# STM32WB05 register map
File version: 0.3
CPU: CM0+ r0p0, little endian, MPU, no FPU, 4 interrupt priority bits
Registers are 32-bit, read-write, reset 0x0 unless marked. A register's access mark holds for its fields unless they carry their own. Offsets are from the block's base; [hi:lo] are bit positions; 'fields as' and 'values as' point back to an identical list.

## RCC
Base 0x48400000
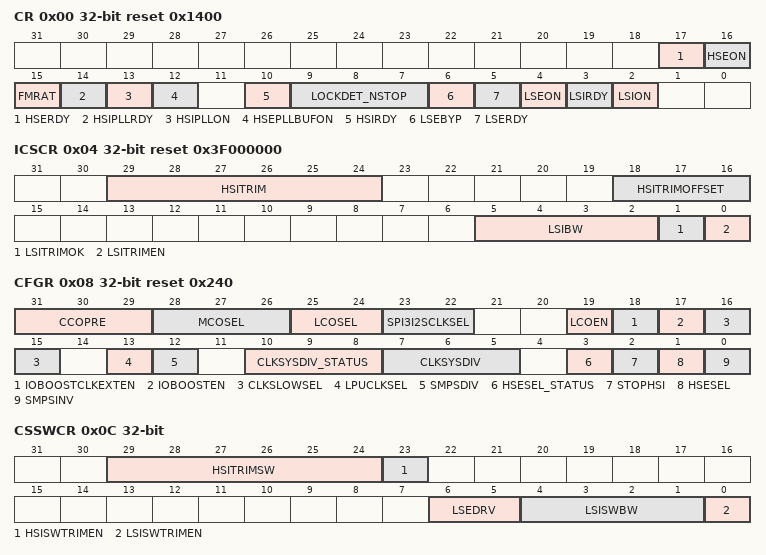
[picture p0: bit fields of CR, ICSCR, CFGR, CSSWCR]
0x00 CR reset 0x1400
  [17] HSERDY ro — External High Speed Clock ready flag. Set by hardware to indicate that HSE oscillator is stable.
    0=HSE oscillator not ready; 1=HSE oscillator ready
  [16] HSEON — External High Speed Clock enable. Set and reset by software. in low power mode, HSE is turned off.
    0=HSE oscillator OFF; 1=HSE oscillator ON
  [15] FMRAT — Force MR_BLE active transmission status (for debug purpose)
    0=no effect; 1=active_transmission is force to '1' whatever the HSIPLLRDY status
  [14] HSIPLLRDY ro — Internal High Speed Clock PLL ready flag.
    0=PLL is unlocked; 1=PLL is locked
  [13] HSIPLLON — Internal High Speed Clock PLL enable
    0=PLL is OFF; 1=PLL is ON
  [12] HSEPLLBUFON — External High Speed Clock Buffer for PLL RF2G4 enable. Set and reset by software.
    0=HSE PLL Buffer OFF; 1=HSE PLL Buffer ON
  [10] HSIRDY ro — Internal High Speed clock ready flag. Set by hardware to indicate that internal RC 64MHz oscillator is stable. This bit is activated only if the RC is enabled by HSION (it is not activated if the RC is enabled by an IP request).
    0=internal RC 64 MHz oscillator not ready; 1=internal RC 64 MHz oscillator ready
  [9:7] LOCKDET_NSTOP — Lock detector Nstop value When start_stop signal is high; a counter is incremented every 16 MHz clock cycle. When the counter reaches (NSTOP+1) x 64 value, the lock_det signal is set high indicating that the PLL is locked. As soon as the start_stop signal is low the counter is reset to 0.
  [6] LSEBYP — External Low Speed Clock bypass. Set and reset by software. Reset source only for this field: PORESETn
    0=LSE oscillator bypass OFF; 1=LSE oscillator bypass ON
  [5] LSERDY ro — External Low Speed Clock ready flag. Set by hardware to indicate that LSE oscillator is stable.
    0=LSE oscillator not ready; 1=LSE oscillator ready
  [4] LSEON — External Low Speed Clock enable. Set and reset by software. Reset source only for this field: PORESETn
    0=LSE oscillator OFF; 1=LSE oscillator ON
  [3] LSIRDY ro — Internal Low Speed oscillator Ready Set and reset by hardware to indicate when the Low Speed Internal RC oscillator is stable. Reset source only for this field: PORESETn
    0=LSI RC oscillator not ready; 1=LSI RC oscillator ready
  [2] LSION — Internal Low Speed oscillator enable Set and reset by software. Reset source only for this field: PORESETn
    0=LSI RC oscillator OFF; 1=LSI RC oscillator ON
0x04 ICSCR reset 0x3F000000
  [29:24] HSITRIM ro — High Speed Internal clock trimming. This value is loaded soon after the completion of the Option Byte Loading procedure. When max value 0x3f is set, HSI is less than 64MHz
  [18:16] HSITRIMOFFSET — ICSCR[18:16] = HSITRIMOFFSET[2:0]: High Speed oscillator signed trimming offset
    0=0 (+ 0 MHz / default); 1=1 (+0.5 MHz); 2=2 (+1MHz); 3=3 (+1.5 MHz); 4=-1 (-0.5 MHz); 5=-2 (-1MHz); 6=-3 (-1.5 MHz); 7=-4 (-2 MHz)
  [5:2] LSIBW ro — Trimming in test mode The value stored is the correspondent Engi Byte and represents the actual value driving the input of the hardware macro. This value is loaded soon after the completion of the Option Byte Loading procedure. This field is directly writeable only in Test Mode.
  [1] LSITRIMOK ro — LSITRIMOK: Low Speed oscillator trimming OK Set and reset by hardware to indicate when the Low Speed Internal RC oscillator has reached an optimal trimming of its bias current; this bit is only valid when LSITRIMEN is active.
    0=LSI Bias trimming (LSIBW) is not good; 1=LSI Bias trimming (LSIBW) value is OK
  [0] LSITRIMEN — Low Speed oscillator trimming enable Set and reset by software. Reset source only for this field: PORESETn
    0=LSI oscillator Bias trimming disabled; 1=LSI oscillator Bias trimming enabled
0x08 CFGR reset 0x240
  [31:29] CCOPRE — Configurable Clock Output Prescaler. Set and reset by software. Glitches propagation if CCOPRE is modified after CCO output is enabled. Others: not used
    0=CCO clock is divided by 1; 1=CCO clock is divided by 2; 2=CCO clock is divided by 4; 3=CCO clock is divided by 8; 4=CCO clock is divided by 16
  [28:26] MCOSEL — Main Configurable Clock Output Selection. Set and reset by software. Glitches propagation possible.
    0=MCO output disabled, no clock on MCO; 1=system clock selected; 2=na; 3=internal RC 64 MHz (HSI) oscillator clock selected; 4=external oscillator (HSE) clock selected; 5=internal RC 64 MHz (HSI) oscillator divided by 2048 and used as slow clock selected; 6=SMPS clock selected; 7=AUX ADC ANA clock selected
  [25:24] LCOSEL — Low speed Configurable Clock Output Selection. Set and reset by software. Glitches propagation possible. Reset source only for this field: PORESETn
    0=LCO output disabled, no clock on LCO; 1=internal 32 KHz (LSI_LPMU) oscillator clock selected; 2=internal 32 KHz (LSI) oscillator clock selected; 3=external 32 KHz (LSE) oscillator clock selected
  [23:22] SPI3I2SCLKSEL — Selection of I2S1 clock: 1x:64MHz peripheral clock
    0=16MHz peripheral clock (default); 1=32MHz peripheral clock
  [19] LCOEN — LCO output enable
  [18] IOBOOSTCLKEXTEN — IO BOOSTER clock enable as external clock Set and reset by software.
    0=does not use rcc clock (default); 1=uses rcc clock
  [17] IOBOOSTEN — IO BOOSTER enable Set and reset by software.
    0=does not enable IO BOOSTER; 1=enable IO BOOSTER
  [16:15] CLKSLOWSEL — slow clock source selection Set by software to select the clock source. This is no glitch free mechanism Reset source only for this field: PORESETn
    0=LSILMPU oscillator clock (default); 1=LSE oscillator clock used as slow clock; 2=LSI oscillator clock used as slow clock; 3=HSI_64M divided by 2048 used as slow clock
  [13] LPUCLKSEL — Selection of LPUART clock:
    0=16MHz peripheral clock (default); 1=LSE clock
  [12] SMPSDIV — SMPS clock prescaling factor to generate 4MHz or 8MHz
    0=div 2 when ANADIV=2 or 4 (default ); 1=div 4 when ANADIV=1 or 2
  [10:8] CLKSYSDIV_STATUS ro — CLKSYSDIV_STATUS: system clock frequency status Set and cleared by hardware to indicate the actual system clock frequency. This register must be read to be sure that the new frequency, selected by CLKSYSDIV, has been applied. 000: system clock frequency is 64 MHz 001: system clock frequency is 32 MHz 010: system clock frequency is 16 MHz 011: system clock frequency is 8 MHz 100: system clock frequency is 4 MHz 101: system clock frequency is 2 MHz 110: system clock frequency is 1 MHz 111: not used. The actual clock frequency switching can be delayed of up to 128 system clock cycles, depending on the RCC internal counter status at the moment the new CLKSYSDIV is applied
  [7:5] CLKSYSDIV — CLKSYSDIV: system clock divided factor from HSI_64M. 000: system clock frequency is 64 MHz (not available when HSESEL=1) 001: system clock frequency is 32 MHz 010: system clock frequency is 16 MHz 011: system clock frequency is 8 MHz * 100: system clock frequency is 4 MHz * 101: system clock frequency is 2 MHz * 110: system clock frequency is 1 MHz * 111: not used. *: If RCC_APB2ENR.MRBLEEN bit is set, writing in CLKSYSDIV one of those values is replaced by a 010b = 16 MHz writing at hardware level. Warning: if the software programs the 64 MHz frequency target while the RCC_CFGR.HSESEL=1, the hardware will switch the system clock tree on HSI64MPLL again (and restart HSIPLL64M analog block if RCC_CFGR.STOPHSI=1) To switch the system frequency between 64 / 32 / 16 MHz without risk when the MR_BLE is used, prefer the RCC_CSCMDR register to change the system frequency. the MR_BLE frequency must always be equal or less than the CPU/system clock to have functional radio.
  [3] HSESEL_STATUS ro — Clock source selection Status
    0=HSI clock source is requested (default); 1=HSE clock source is requested
  [2] STOPHSI — Stop HSI clock source request
    0=HSI is enabled (default); 1=disable HSI is requested
  [1] HSESEL — Clock source selection request:
    values as HSESEL_STATUS
  [0] SMPSINV — bit to control inversion of the SMPS clock
    0=SMPS clock not inverted (default value); 1=SMPS clock inverted (for debug)
0x0C CSSWCR
  [29:24] HSITRIMSW — High Speed Internal clock trimming value to set by SW.
  [23] HSISWTRIMEN — High Speed oscillator trimming by SW enable Set and reset by software.
    0=HSI oscillator Bias trimming by SW disabled; 1=HSI oscillator Bias trimming by SW enabled
  [6:5] LSEDRV — Maximum Crystal gm for Low Speed External XO (to connect to XTDRV of 32kHz LSE XO => into IO V33?) to amplify drinving capacity modulation Set by software. Reset source only for this field: PORESETn
    0=0.0, low drive capability; 1=0.1, medium low drive capability; 2=1.0, medium high drive capability; 3=1.1, highdrive capability
  [4:1] LSISWBW — Low Speed Internal clock trimming value to set by SW Reset source only for this field: PORESETn
  [0] LSISWTRIMEN — Low Speed oscillator trimming by SW enable Set and reset by software. Reset source only for this field: PORESETn
    0=LSI oscillator Bias trimming by SW disabled; 1=LSI oscillator Bias trimming by SW enabled
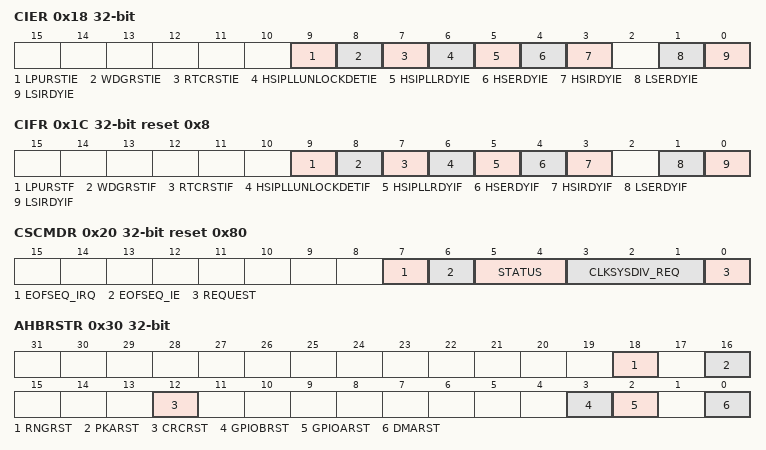
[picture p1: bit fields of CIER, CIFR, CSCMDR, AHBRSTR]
0x18 CIER
  [9] LPURSTIE — LPURSTIE: LPUART reset release interrupt enable.
    0=LPUART reset release interrupt is disabled; 1=LPUART reset release interrupt is enabled
  [8] WDGRSTIE — WDGRSTIE: Watchdog reset end Interrupt Enable. Set and reset by software to enable/disable interrupt caused by the watchdog reset end.
    0=interrupt disabled; 1=interrupt enabled
  [7] RTCRSTIE — RTCRSTIE: RTC reset end Interrupt Enable. Set and reset by software to enable/disable interrupt caused by the RTC reset end.
    0=HSI PLL unlock detection interrupt disabled; 1=HSI PLL unlock detection interrupt enabled
  [6] HSIPLLUNLOCKDETIE — HSIPLLUNLOCKDETIE: HSI PLL unlock detection Interrupt Enable. Set and reset by software to enable/disable interrupt caused by the HSI 64MHz PLL unlock.
    values as RTCRSTIE
  [5] HSIPLLRDYIE — HSI PLL Ready Interrupt Enable. Set and reset by software to enable/disable interrupt caused by the HSI 64MHz PLL locked on HSE.
    0=HSI PLL ready interrupt disabled; 1=HSI PLL ready interrupt enabled
  [4] HSERDYIE — HSE Ready Interrupt Enable Set and reset by software to enable/disable interrupt caused by the external HSE oscillator stabilization.
    0=HSE ready interrupt disabled; 1=HSE ready interrupt enabled
  [3] HSIRDYIE — HSI Ready Interrupt Enable. Set and reset by software to enable/disable interrupt caused by the internal RC 64MHz oscillator stabilization.
    0=HSI ready interrupt disabled; 1=HSI ready interrupt enabled
  [1] LSERDYIE — LSE Ready Interrupt Enable. Set and reset by software to enable/disable interrupt caused by the external 32 kHz oscillator stabilization.
    0=LSE ready interrupt disabled; 1=LSE ready interrupt enabled
  [0] LSIRDYIE — LSI Ready Interrupt Enable. Set and reset by software to enable/disable interrupt caused by internal RC 32 kHz oscillator stabilization.
    0=LSI ready interrupt disabled; 1=LSI ready interrupt enabled
0x1C CIFR reset 0x8
  [9] LPURSTF — LPUART reset release flag
    0=no LPUART reset release event occurred; 1=LPUART reset release event occurred
  [8] WDGRSTIF — WDG reset end Interrupt Flag. Raised when reset is released on 32kHz clock
  [7] RTCRSTIF — RTC reset end Interrupt Flag. Raised when reset is released on 32kHz clock
  [6] HSIPLLUNLOCKDETIF — HSIPLLUNLOCKDETIF: HSI PLL unlock detection Interrupt Flag.
  [5] HSIPLLRDYIF — HSI PLL Ready Interrupt Flag. Set by hardware when HSI PLL 64MHz becomes stable.
    0=No clock ready interrupt caused by the HSI PLL64 MHz oscillator; 1=Clock ready interrupt caused by the HSI PLL64 MHz oscillator
  [4] HSERDYIF — HSE Ready Interrupt Flag. Set by hardware when HSE becomes stable.
    0=No clock ready interrupt caused by the HSE oscillator; 1=Clock ready interrupt caused by the HSE oscillator
  [3] HSIRDYIF — HSI Ready Interrupt Flag. Set by hardware when HSI becomes stable.
    0=No clock ready interrupt caused by the HSI oscillator; 1=Clock ready interrupt caused by the HSI oscillator
  [1] LSERDYIF — LSE Ready Interrupt Flag. Set by hardware when LSE clock becomes stable.
    0=No clock ready interrupt caused by the LSE oscillator; 1=Clock ready interrupt caused by the LSE oscillator
  [0] LSIRDYIF — LSI Ready Interrupt flag Set by hardware when LSI clock becomes stable.
    0=No clock ready interrupt caused by the internal RC 32 KHz oscillator; 1=Clock ready interrupt caused by the internal RC 32 kHz oscillator
0x20 CSCMDR reset 0x80
  [7] EOFSEQ_IRQ — End of Sequence flag Set by hardware when clock system swtich is ended
    0=No end of sequence event occured; 1=End of sequece event occured
  [6] EOFSEQ_IE — End of sequence Interrupt Enable. Set and reset by software to enable/disable interrupt caused by the clock system switch.
    0=End of sequence interrupt disabled; 1=End of sequence interrupt enabled
  [5:4] STATUS ro — Status of clock switch sequence
    0=IDLE no switch requested; 1=ONGOING clock frequency switch is ongoing; 2=DONE clock frequency switch done
  [3:1] CLKSYSDIV_REQ — system clock dividing factor from HSI_64M requested Note: behavior depends on BLEEN in APB2ENR register
    0=div 1 (sys clock 64M); 1=div 2 (sys clock 32M); 2=div 4 (sys clock 16M); 3=div 8 (sys clock 8M); 4=div 16 (sys clock 4M); 5=div 32 (sys clock 2M); 6=div 64 (sys clock 1M)
  [0] REQUEST — Request for system clock switching Cleared by hardware when system clock frequency switch is done
    0=To cancel an ongiong request - still possible until IRQ assertion; 1=To update the system clock frequency
0x30 AHBRSTR
  [18] RNGRST — RNG reset Set and reset by software.
    0=does not reset; 1=resets
  [16] PKARST — PKA reset Set and reset by software.
    0=does not reset; 1=resets
  [12] CRCRST — CRC reset Set and reset by software.
    0=does not reset CRC; 1=resets CRC
  [3] GPIOBRST — GPIOB reset Set and reset by software.
    0=does not reset; 1=resets
  [2] GPIOARST — GPIOA reset Set and reset by software.
    0=does not reset; 1=resets
  [0] DMARST — DMA and DMAMUX reset Set and reset by software.
    0=does not reset DMA; 1=resets DMA
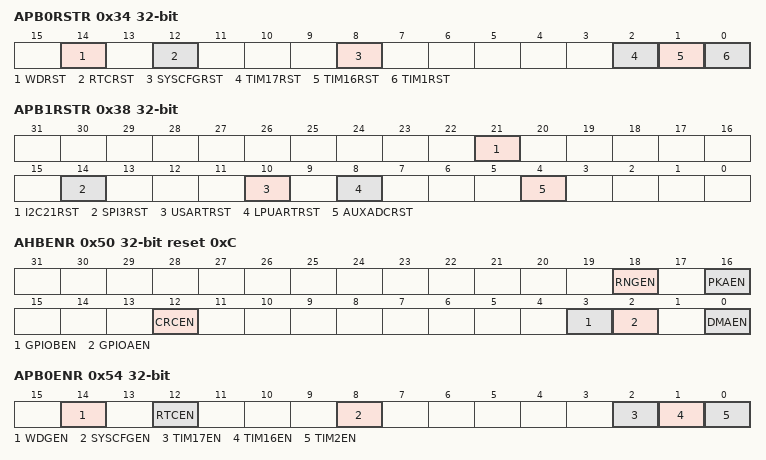
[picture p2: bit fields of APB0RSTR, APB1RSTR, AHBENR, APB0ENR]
0x34 APB0RSTR
  [14] WDRST — WATCHDOG reset Set and reset by software.
    0=does not reset; 1=resets
  [12] RTCRST — RTC reset Set and reset by software.
    0=does not reset; 1=resets
  [8] SYSCFGRST — SYSTEM CONFIG reset Set and reset by software.
    0=does not reset; 1=resets
  [2] TIM17RST — TIM17 reset
    0=TIM17 IP is not under reset; 1=TIM17 IP is under reset
  [1] TIM16RST — TIM16 reset
    0=TIM16 IP is not under reset; 1=TIM16 IP is under reset
  [0] TIM1RST — TIM1: Advanced Timer reset Set and reset by software.
    0=does not reset; 1=resets
0x38 APB1RSTR
  [all] fields
    0=does not reset; 1=resets
  [21] I2C21RST — I2C1 reset Set and reset by software.
  [14] SPI3RST — SPI3 reset Set and reset by software.
  [10] USARTRST — USART reset Set and reset by software.
  [8] LPUARTRST — LPUART reset Set and reset by software.
  [4] AUXADCRST — AUXADC reset for Aux-ADC digital clock Set and reset by software.
0x40 APB2RSTR
  [0] BLERST — BLE reset.
0x50 AHBENR reset 0xC
  [18] RNGEN — RNG clock enable Set and enable by software.
    0=does not enable; 1=enable
  [16] PKAEN — PKA clock enable Set and enable by software.
    0=does not enable; 1=enable
  [12] CRCEN — CRC enable Set and enable by software.
    0=does not enable; 1=enable
  [3] GPIOBEN — GPIOB enable. It must be enabled by default
  [2] GPIOAEN — GPIOA enable. It must be enabled by default
  [0] DMAEN — DMA and DMAMUX enable Set and enable by software.
    0=does not enable; 1=enable
0x54 APB0ENR
  [14] WDGEN — Watchdog clock enable. Set and enable by software.
    0=does not enable; 1=enable
  [12] RTCEN — RTC clock enable Set and enable by software. Reset source only for this field: PORESETn
    0=does not enable; 1=enable
  [8] SYSCFGEN — SYSTEM CONFIG enable Set and enable by software.
    0=does not enable; 1=enable
  [2] TIM17EN — TIM17 enable
    0=TIM17 IP is clock gated; 1=TIM17 IP is clocked
  [1] TIM16EN — TIM16 enable
    0=TIM16 IP is clock gated; 1=TIM16 IP is clocked
  [0] TIM2EN — TIM2: Advanced Timer clock enable Set and enable by software.
    0=does not enable; 1=enable
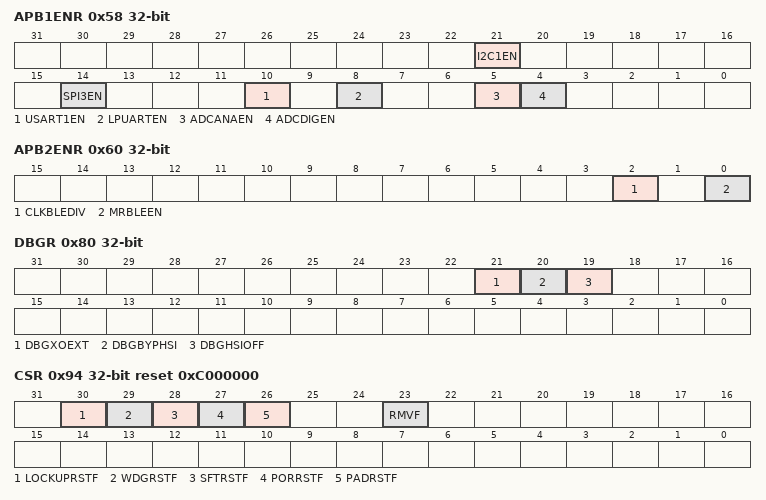
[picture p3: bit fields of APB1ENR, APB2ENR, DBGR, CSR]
0x58 APB1ENR
  [all] fields
    0=does not enable; 1=enable
  [21] I2C1EN — I2C1 clock enable Set and enable by software.
  [14] SPI3EN — SPI3 clock enable Set and enable by software.
  [10] USART1EN — USART clock enable Set and enable by software.
  [8] LPUARTEN — LPUART clock enable Set and enable by software.
  [5] ADCANAEN — ADC clock enable for Aux-ADC analog clock Set and enable by software.
  [4] ADCDIGEN — AUXADC clock enable for Aux-ADC digital clock Set and enable by software.
0x60 APB2ENR
  [2] CLKBLEDIV — MR_BLE clock frequency selection when RCC_APB2ENR.MRBLEEN=1
    0=32MHz; 1=16MHz
  [0] MRBLEEN — MR_BLE enable
    0=MR_BLE IP is clock gated; 1=MR_BLE IP is clocked
0x80 DBGR
  [21] DBGXOEXT — used for debug mode with HSE bypassed by FXTAL_IN clock and ZIV12 output used.
  [20] DBGBYPHSI — used for debug mode with HSI bypassed by HSE
  [19] DBGHSIOFF — used for debug or test
0x94 CSR reset 0xC000000
  [30] LOCKUPRSTF ro — LOCK UP reset flag from CM0 Reset by software by writing the RMVF bit. Set by hardware from unrecoverable exception CPU. It reset V12i domain, FLASH controller and peripherals.
    0=No lockup reset occurred; 1=lockup reset occurred
  [29] WDGRSTF ro — Watchdog reset flag Reset by software by writing the RMVF bit. Set by hardware when a watchdog reset from V33 domain occurs.
    0=No watchdog reset occurred; 1=Watchdog reset occurred
  [28] SFTRSTF ro — Software reset flag Reset by software by writing the RMVF bit. Set by hardware when a software reset occurs.
    0=No software reset occurred; 1=Software reset occurred
  [27] PORRSTF ro — POWER reset flag Reset by software by writing the RMVF bit. Set by hardware when a power reset occurs from LPMURESET block.
    0=No POWER reset occurred; 1=POWER reset occurred
  [26] PADRSTF ro — SYSTEM reset flag Reset by software by writing the RMVF bit. Set by hardware when a reset from pad occurs.
    0=No reset from pad occurred; 1=Reset from pad occurred
  [23] RMVF wo — Remove reset flag Set by software to clear the value of the reset flags. It auto clears by HW after clearing reason flags
    0=Nothing done; 1=Reset the value of the reset flags
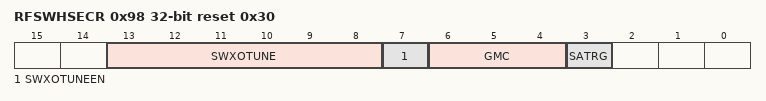
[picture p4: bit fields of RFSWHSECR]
0x98 RFSWHSECR reset 0x30
  [13:8] SWXOTUNE — RF-HSE capacitor bank tuning value by SW Set by software
  [7] SWXOTUNEEN — RF-HSE capacitor bank tuning by SW enable Set by software
  [6:4] GMC — High Speed External XO current control Set by software.
    0=max 0.0 001: max 0.57 mA/V; 2=max 0.78 mA/V; 3=max 1.13 mA/V (Default); 4=max 0.61 mA/V; 5=max 1.65 mA/V; 6=max 2.12 mA/V; 7=max 2.84 mA/V
  [3] SATRG — Sense Amplifier threshold Set by software.
    0=the bias current is confronted to a reference current with a ratio of 1/2; 1=the bias current is confronted to a reference current with a ratio of 3/4
0x9C RFHSECR ro
  [5:0] XOTUNE — RF-HSE capacitor bank tuning Set by option byte loading soon after Power On Reset.
